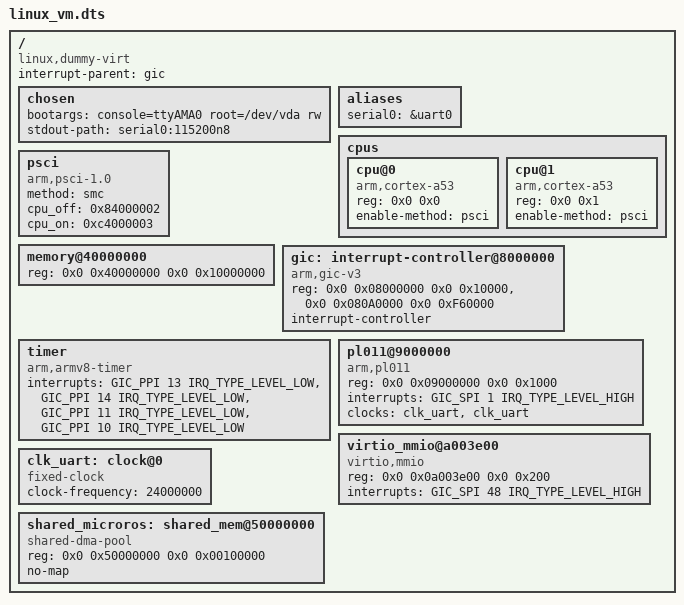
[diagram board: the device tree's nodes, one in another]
/dts-v1/;

/ {
    compatible = "linux,dummy-virt";
    #address-cells = <2>;
    #size-cells = <2>;
    interrupt-parent = <&gic>;

    chosen {
        bootargs = "console=ttyAMA0 root=/dev/vda rw";
        stdout-path = "serial0:115200n8";
    };

    aliases {
        serial0 = &uart0;
    };

    cpus {
        #address-cells = <2>;
        #size-cells = <0>;

        cpu@0 {
            device_type = "cpu";
            compatible = "arm,cortex-a53";
            reg = <0x0 0x0>;
            enable-method = "psci";
        };

        cpu@1 {
            device_type = "cpu";
            compatible = "arm,cortex-a53";
            reg = <0x0 0x1>;
            enable-method = "psci";
        };
    };

    psci {
        compatible = "arm,psci-1.0";
        method = "smc";
        cpu_off = <0x84000002>;
        cpu_on = <0xc4000003>;
    };

    memory@40000000 {
        device_type = "memory";
        reg = <0x0 0x40000000 0x0 0x10000000>;
    };

    gic: interrupt-controller@8000000 {
        compatible = "arm,gic-v3";
        #interrupt-cells = <3>;
        #address-cells = <2>;
        #size-cells = <2>;
        ranges;
        reg = <0x0 0x08000000 0x0 0x10000>,    /* GICD */
              <0x0 0x080A0000 0x0 0xF60000>;   /* GICR */
        interrupt-controller;
    };

    timer {
        compatible = "arm,armv8-timer";
        interrupts = <GIC_PPI 13 IRQ_TYPE_LEVEL_LOW>,
                     <GIC_PPI 14 IRQ_TYPE_LEVEL_LOW>,
                     <GIC_PPI 11 IRQ_TYPE_LEVEL_LOW>,
                     <GIC_PPI 10 IRQ_TYPE_LEVEL_LOW>;
    };

    pl011@9000000 {
        compatible = "arm,pl011";
        reg = <0x0 0x09000000 0x0 0x1000>;
        interrupts = <GIC_SPI 1 IRQ_TYPE_LEVEL_HIGH>;
        clocks = <&clk_uart>, <&clk_uart>;
        clock-names = "uartclk", "apb_pclk";
    };

    virtio_mmio@a003e00 {
        compatible = "virtio,mmio";
        reg = <0x0 0x0a003e00 0x0 0x200>;
        interrupts = <GIC_SPI 48 IRQ_TYPE_LEVEL_HIGH>;
    };

    clk_uart: clock@0 {
        compatible = "fixed-clock";
        #clock-cells = <0>;
        clock-frequency = <24000000>;
    };

    /* Shared memory region for micro-ROS communication */
    shared_microros: shared_mem@50000000 {
        compatible = "shared-dma-pool";
        reg = <0x0 0x50000000 0x0 0x00100000>;
        no-map;
    };
};
